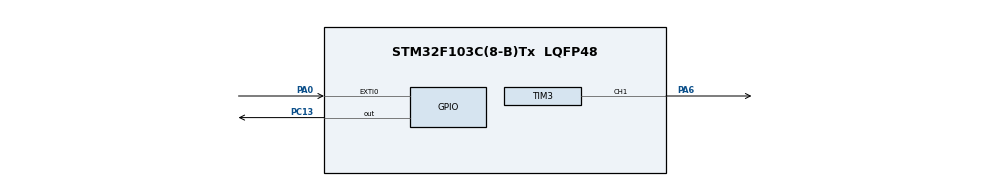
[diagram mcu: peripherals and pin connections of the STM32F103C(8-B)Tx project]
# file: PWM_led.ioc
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Mcu.Family=STM32F1
Mcu.Name=STM32F103C(8-B)Tx
Mcu.Package=LQFP48
NVIC.EXTI0_IRQn=true\:6\:0\:true\:false\:true\:true\:true\:true
NVIC.PriorityGroup=NVIC_PRIORITYGROUP_4
NVIC.TIM1_UP_IRQn=true\:15\:0\:false\:false\:true\:false\:true\:true
NVIC.TIM3_IRQn=true\:6\:0\:true\:false\:true\:true\:true\:true
NVIC.TimeBase=TIM1_UP_IRQn
NVIC.TimeBaseIP=TIM1
PA0-WKUP.GPIO_PuPd=GPIO_PULLUP
PA0-WKUP.Signal=GPXTI0
PA13.Mode=JTAG_4_pins
PA13.Signal=SYS_JTMS-SWDIO
PA14.Mode=JTAG_4_pins
PA14.Signal=SYS_JTCK-SWCLK
PA15.Mode=JTAG_4_pins
PA15.Signal=SYS_JTDI
PA6.Signal=S_TIM3_CH1
PB3.Mode=JTAG_4_pins
PB3.Signal=SYS_JTDO-TRACESWO
PC13-TAMPER-RTC.Signal=GPIO_Output
ProjectManager.HeapSize=0x200
ProjectManager.StackSize=0x400
ProjectManager.TargetToolchain=STM32CubeIDE
RCC.APB1Freq_Value=8000000
RCC.APB2Freq_Value=8000000
SH.S_TIM3_CH1.0=TIM3_CH1,PWM Generation1 CH1
TIM3.AutoReloadPreload=TIM_AUTORELOAD_PRELOAD_ENABLE
TIM3.Channel-PWM\ Generation1\ CH1=TIM_CHANNEL_1
TIM3.Period=99
TIM3.Prescaler=800
TIM3.Pulse-PWM\ Generation1\ CH1=9
TIM3.TIM_MasterOutputTrigger=TIM_TRGO_RESET
TIM3.TIM_MasterSlaveMode=TIM_MASTERSLAVEMODE_DISABLE
VP_SYS_VS_tim1.Mode=TIM1
board=custom

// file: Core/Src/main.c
/* USER CODE BEGIN Header */
/**
  ******************************************************************************
  * @file           : main.c
  * @brief          : Main program body
  ******************************************************************************
  * @attention
  *
  * Copyright (c) 2025 STMicroelectronics.
  * All rights reserved.
  *
  * This software is licensed under terms that can be found in the LICENSE file
  * in the root directory of this software component.
  * If no LICENSE file comes with this software, it is provided AS-IS.
  *
  ******************************************************************************
  */
/* USER CODE END Header */
#include "main.h"

/* USER CODE BEGIN Includes */
#include "FreeRTOS.h"
#include "task.h"
/* USER CODE END Includes */

/* USER CODE BEGIN PD */
BaseType_t Status;
TaskHandle_t myTaskHandler;
/* USER CODE END PD */

TIM_HandleTypeDef htim3;

/* USER CODE BEGIN PV */
uint16_t PWM_VAL;
uint8_t LED_polarity = 0;

/* USER CODE END PV */

void SystemClock_Config(void);
static void MX_GPIO_Init(void);
static void MX_TIM3_Init(void);
/* USER CODE BEGIN PFP */
void TaksFunction(void* vParameters);
/* USER CODE END PFP */

int main(void)
{

  /* MCU Configuration--------------------------------------------------------*/

  /* Reset of all peripherals, Initializes the Flash interface and the Systick. */
  HAL_Init();

  /* Configure the system clock */
  SystemClock_Config();

  /* Initialize all configured peripherals */
  MX_GPIO_Init();
  MX_TIM3_Init();
  /* USER CODE BEGIN 2 */
  Status = xTaskCreate(TaksFunction, "Timer task", 100, NULL, 0, &myTaskHandler);
  configASSERT(Status == pdPASS);

  HAL_TIM_Base_Start_IT(&htim3);
  HAL_TIM_PWM_Start_IT(&htim3, TIM_CHANNEL_1);

  PWM_VAL = htim3.Instance->CCR1;

  vTaskStartScheduler();
  /* USER CODE END 2 */

  /* Infinite loop */
  while (1)
  {

  }
}

void SystemClock_Config(void)
{
  RCC_OscInitTypeDef RCC_OscInitStruct = {0};
  RCC_ClkInitTypeDef RCC_ClkInitStruct = {0};

  /** Initializes the RCC Oscillators according to the specified parameters
  * in the RCC_OscInitTypeDef structure.
  */
  RCC_OscInitStruct.OscillatorType = RCC_OSCILLATORTYPE_HSI;
  RCC_OscInitStruct.HSIState = RCC_HSI_ON;
  RCC_OscInitStruct.HSICalibrationValue = RCC_HSICALIBRATION_DEFAULT;
  RCC_OscInitStruct.PLL.PLLState = RCC_PLL_NONE;
  if (HAL_RCC_OscConfig(&RCC_OscInitStruct) != HAL_OK)
  {
    Error_Handler();
  }

  /** Initializes the CPU, AHB and APB buses clocks
  */
  RCC_ClkInitStruct.ClockType = RCC_CLOCKTYPE_HCLK|RCC_CLOCKTYPE_SYSCLK
                              |RCC_CLOCKTYPE_PCLK1|RCC_CLOCKTYPE_PCLK2;
  RCC_ClkInitStruct.SYSCLKSource = RCC_SYSCLKSOURCE_HSI;
  RCC_ClkInitStruct.AHBCLKDivider = RCC_SYSCLK_DIV1;
  RCC_ClkInitStruct.APB1CLKDivider = RCC_HCLK_DIV1;
  RCC_ClkInitStruct.APB2CLKDivider = RCC_HCLK_DIV1;

  if (HAL_RCC_ClockConfig(&RCC_ClkInitStruct, FLASH_LATENCY_0) != HAL_OK)
  {
    Error_Handler();
  }
}

static void MX_TIM3_Init(void)
{

  TIM_MasterConfigTypeDef sMasterConfig = {0};
  TIM_OC_InitTypeDef sConfigOC = {0};

  htim3.Instance = TIM3;
  htim3.Init.Prescaler = 800;
  htim3.Init.CounterMode = TIM_COUNTERMODE_UP;
  htim3.Init.Period = 99;
  htim3.Init.ClockDivision = TIM_CLOCKDIVISION_DIV1;
  htim3.Init.AutoReloadPreload = TIM_AUTORELOAD_PRELOAD_ENABLE;
  if (HAL_TIM_PWM_Init(&htim3) != HAL_OK)
  {
    Error_Handler();
  }
  sMasterConfig.MasterOutputTrigger = TIM_TRGO_RESET;
  sMasterConfig.MasterSlaveMode = TIM_MASTERSLAVEMODE_DISABLE;
  if (HAL_TIMEx_MasterConfigSynchronization(&htim3, &sMasterConfig) != HAL_OK)
  {
    Error_Handler();
  }
  sConfigOC.OCMode = TIM_OCMODE_PWM1;
  sConfigOC.Pulse = 9;
  sConfigOC.OCPolarity = TIM_OCPOLARITY_HIGH;
  sConfigOC.OCFastMode = TIM_OCFAST_DISABLE;
  if (HAL_TIM_PWM_ConfigChannel(&htim3, &sConfigOC, TIM_CHANNEL_1) != HAL_OK)
  {
    Error_Handler();
  }
  HAL_TIM_MspPostInit(&htim3);

}

static void MX_GPIO_Init(void)
{
  GPIO_InitTypeDef GPIO_InitStruct = {0};

  /* GPIO Ports Clock Enable */
  __HAL_RCC_GPIOC_CLK_ENABLE();
  __HAL_RCC_GPIOA_CLK_ENABLE();
  __HAL_RCC_GPIOB_CLK_ENABLE();

  /*Configure GPIO pin Output Level */
  HAL_GPIO_WritePin(GPIOC, GPIO_PIN_13, GPIO_PIN_RESET);

  /*Configure GPIO pin : PC13 */
  GPIO_InitStruct.Pin = GPIO_PIN_13;
  GPIO_InitStruct.Mode = GPIO_MODE_OUTPUT_PP;
  GPIO_InitStruct.Pull = GPIO_NOPULL;
  GPIO_InitStruct.Speed = GPIO_SPEED_FREQ_LOW;
  HAL_GPIO_Init(GPIOC, &GPIO_InitStruct);

  /*Configure GPIO pin : PA0 */
  GPIO_InitStruct.Pin = GPIO_PIN_0;
  GPIO_InitStruct.Mode = GPIO_MODE_IT_RISING;
  GPIO_InitStruct.Pull = GPIO_PULLUP;
  HAL_GPIO_Init(GPIOA, &GPIO_InitStruct);

  /* EXTI interrupt init*/
  HAL_NVIC_SetPriority(EXTI0_IRQn, 6, 0);
  HAL_NVIC_EnableIRQ(EXTI0_IRQn);

}

/* USER CODE BEGIN 4 */
void TaksFunction(void* vParameters)
{
	for(;;)
	{
		/*infinite loop */
	}
}

void HAL_TIM_OC_DelayElapsedCallback(TIM_HandleTypeDef *htim)
{

	if (htim->Instance == TIM3) {
		if(LED_polarity)
		{
			HAL_GPIO_WritePin(GPIOC, GPIO_PIN_13, ENABLE);
		}else{
			HAL_GPIO_WritePin(GPIOC, GPIO_PIN_13, DISABLE);
		}
	}

}

void HAL_GPIO_EXTI_Callback(uint16_t GPIO_Pin)
{

	TIM_TypeDef* my_TIM3 = (TIM_TypeDef*)0x40000400UL;

	if(GPIO_Pin == GPIO_PIN_0)
	{
		my_TIM3->CCR1 = PWM_VAL;
		PWM_VAL += 15;
		if(PWM_VAL > my_TIM3->ARR )
		{
			PWM_VAL = 9;
		}

		my_TIM3->CCR1 = PWM_VAL;
	}

}

/* USER CODE END 4 */

void HAL_TIM_PeriodElapsedCallback(TIM_HandleTypeDef *htim)
{
  /* USER CODE BEGIN Callback 0 */
	if (htim->Instance == TIM3) {
		if(LED_polarity)
		{
			HAL_GPIO_WritePin(GPIOC, GPIO_PIN_13, DISABLE);
		}else{
			HAL_GPIO_WritePin(GPIOC, GPIO_PIN_13, ENABLE);
		}
	}

  /* USER CODE END Callback 0 */
  if (htim->Instance == TIM1) {
    HAL_IncTick();
  }
}

void Error_Handler(void)
{
  __disable_irq();
  while (1)
  {
  }
}
